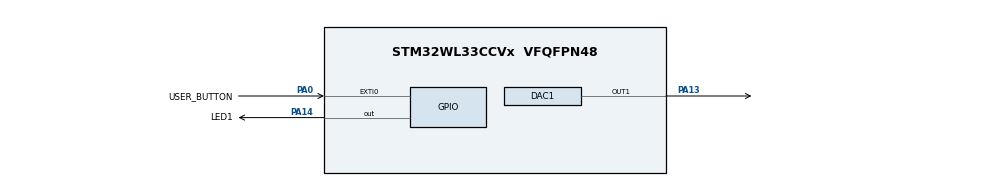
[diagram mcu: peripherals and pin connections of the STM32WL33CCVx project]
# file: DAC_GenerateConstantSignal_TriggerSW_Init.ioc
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DAC1.DAC_Trigger-DAC_OUT1=DAC_TRIGGER_SOFTWARE
Mcu.Family=STM32WL3
Mcu.Name=STM32WL33CCVx
Mcu.Package=VFQFPN48
NVIC.DAC_IRQn=true\:0\:0\:false\:false\:true\:true\:true\:true
NVIC.GPIOA_IRQn=true\:0\:0\:false\:false\:true\:true\:true\:true
OSCIN.Mode=HSE-External-Oscillator
OSCIN.Signal=RCC_OSC_IN
OSCOUT.Mode=HSE-External-Oscillator
OSCOUT.Signal=RCC_OSC_OUT
PA0.GPIO_Label=USER_BUTTON
PA0.GPIO_ModeDefaultEXTI=GPIO_MODE_IT_FALLING
PA0.GPIO_PuPd=GPIO_PULLUP
PA0.Signal=GPXTI0
PA13.Signal=COMP_DAC11_group
PA14.GPIO_Label=LED1
PA14.Signal=GPIO_Output
ProjectManager.HeapSize=0x000
ProjectManager.StackSize=0xC00
ProjectManager.TargetToolchain=EWARM V9.30
RCC.HSE_VALUE=48000000
RCC.HSI_VALUE=64000000
RCC.LSE_VALUE=32768
RCC.RC64MPLLSource=RCC_LSCOSOURCE_PLL64
SH.COMP_DAC11_group.0=DAC1_OUT1,DAC_OUT1
VP_PWR_VS_SECSignals.Mode=Security/Privilege
board=custom

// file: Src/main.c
/* USER CODE BEGIN Header */
/**
  ******************************************************************************
  * @file    Examples_LL/DAC/DAC_GenerateConstantSignal_TriggerSW_Init/Src/main.c
  * @author  MCD Application Team
  * @brief   This example describes how to use the DAC peripheral to generate
  *          a constant voltage signal.
  *          This example is based on the STM32WL3x DAC LL API;
  *          Peripheral initialization done using LL unitary services functions.
  ******************************************************************************
  * @attention
  *
  * Copyright (c) 2024 STMicroelectronics.
  * All rights reserved.
  *
  * This software is licensed under terms that can be found in the LICENSE file
  * in the root directory of this software component.
  * If no LICENSE file comes with this software, it is provided AS-IS.
  *
  ******************************************************************************
  */
/* USER CODE END Header */
#include "main.h"

/* USER CODE BEGIN PD */
/* Definitions of environment analog values */
  /* Value of analog reference voltage (Vref+), connected to analog voltage   */
  /* supply Vdda (unit: mV).                                                  */
  #define VDDA_APPLI                       ((uint32_t)3300)

/* Definitions of data related to this example */
  /* Full-scale digital value with a resolution of 6 bits (voltage range     */
  /* determined by analog voltage references Vref+ and Vref-,                 */
  /* refer to reference manual).                                              */
  #define DIGITAL_SCALE_6BITS             (__LL_DAC_DIGITAL_SCALE(LL_DAC_RESOLUTION_6B))

/* USER CODE END PD */

/* USER CODE BEGIN PV */
__IO uint8_t ubButtonPress = 0;
__IO uint8_t ubButtonPressCount = 0;

/* USER CODE END PV */

void SystemClock_Config(void);
void PeriphCommonClock_Config(void);
static void MX_GPIO_Init(void);
static void MX_DAC1_Init(void);
/* USER CODE BEGIN PFP */
void     Activate_DAC(void);
void     LED_On(void);
void     LED_Off(void);
void     LED_Toggle(void);
void     LED_Blinking(uint32_t Period);
void     WaitForUserButtonPress(void);
/* USER CODE END PFP */

int main(void)
{

  /* MCU Configuration--------------------------------------------------------*/

  /* Reset of all peripherals, Initializes the Flash interface and the Systick. */
  LL_APB0_GRP1_EnableClock(LL_APB0_GRP1_PERIPH_SYSCFG);

  /* USER CODE BEGIN Init */
  NVIC_SetPriorityGrouping(NVIC_PRIORITYGROUP_2);
  /* USER CODE END Init */

  /* Configure the system clock */
  SystemClock_Config();

  /* Configure the peripherals common clocks */
  PeriphCommonClock_Config();

  /* Initialize all configured peripherals */
  MX_GPIO_Init();
  MX_DAC1_Init();
  /* USER CODE BEGIN 2 */
  /* Wait for USER push-button press */
  WaitForUserButtonPress();

  /* Turn-off LD1 */
  LED_Off();

  /* Activate DAC channel */
  Activate_DAC();

  /* Turn-on LD1 */
  LED_On();
  /* USER CODE END 2 */

  /* Infinite loop */
  /* USER CODE BEGIN WHILE */
  while (1)
  {
    /* Note: LED state depending and DAC channel output are set into          */
    /*       function "UserButton_Callback()".                                */
    /* USER CODE END WHILE */

  }
}

void SystemClock_Config(void)
{

   /* Set HSE Capacitor Tuning */
  LL_RCC_HSE_SetCapacitorTuning(CFG_HW_RCC_HSE_CAPACITOR_TUNE);

   /* Set HSE startup Current */
 LL_RCC_HSE_SetStartupCurrent(0);

   /* Set HSE Amplitude Threshold */
 LL_RCC_HSE_SetAmplitudeThreshold(0);

   /* Set HSE Current Control */
  LL_RCC_HSE_SetCurrentControl(40);

   /* Enable the HSE */
  LL_RCC_HSE_Enable();

   /* Wait till HSE is ready */
  while(LL_RCC_HSE_IsReady() != 1)
  {
  }

  LL_FLASH_SetLatency(LL_FLASH_WAIT_STATES_1);

   /* Enable the RC64MPLL*/
  LL_RCC_RC64MPLL_Enable();

   /* Wait till RC64MPLL is ready */
  while(LL_RCC_RC64MPLL_IsReady() != 1)
  {
  }

  LL_RCC_SetRC64MPLLPrescaler(LL_RCC_RC64MPLL_DIV_1);

   /* Update the SystemCoreClock global variable */
  LL_SetSystemCoreClock(64000000);

   /* Configure the source of time base considering new system clocks settings*/
  LL_Init1msTick(64000000);
}

void PeriphCommonClock_Config(void)
{
  LL_RCC_SetSMPSPrescaler(LL_RCC_SMPS_DIV_2);

   /* Enable the KRM*/
  LL_RCC_KRM_Enable();
  LL_RCC_KRM_SetRateMultiplier(2);
}

static void MX_DAC1_Init(void)
{

  LL_DAC_InitTypeDef DAC_InitStruct = {0};

  LL_GPIO_InitTypeDef GPIO_InitStruct = {0};

  /* Peripheral clock enable */
  LL_APB0_GRP1_EnableClock(LL_APB0_GRP1_PERIPH_DAC);

  LL_AHB1_GRP1_EnableClock(LL_AHB1_GRP1_PERIPH_GPIOA);
  /**DAC1 GPIO Configuration
  PA13   ------> DAC1_OUT1
  */
  GPIO_InitStruct.Pin = LL_GPIO_PIN_13;
  GPIO_InitStruct.Mode = LL_GPIO_MODE_ANALOG;
  GPIO_InitStruct.Pull = LL_GPIO_PULL_NO;
  LL_GPIO_Init(GPIOA, &GPIO_InitStruct);

  /* DAC1 interrupt Init */
  NVIC_SetPriority(DAC_IRQn, 0);
  NVIC_EnableIRQ(DAC_IRQn);

  /** DAC channel OUT1 config
  */
  DAC_InitStruct.TriggerSource = LL_DAC_TRIG_SOFTWARE;
  DAC_InitStruct.WaveAutoGeneration = LL_DAC_WAVE_AUTO_GENERATION_NONE;
  DAC_InitStruct.OutputBuffer = LL_DAC_OUTPUT_BUFFER_ENABLE;
  LL_DAC_Init(DAC1, LL_DAC_CHANNEL_1, &DAC_InitStruct);
  LL_DAC_EnableTrigger(DAC1, LL_DAC_CHANNEL_1);

}

static void MX_GPIO_Init(void)
{
  LL_GPIO_InitTypeDef GPIO_InitStruct = {0};

  /* GPIO Ports Clock Enable */
  LL_AHB1_GRP1_EnableClock(LL_AHB1_GRP1_PERIPH_GPIOA);

  /**/
  LL_GPIO_ResetOutputPin(LED1_GPIO_Port, LED1_Pin);

  /**/
  LL_GPIO_SetPinPull(USER_BUTTON_GPIO_Port, USER_BUTTON_Pin, LL_GPIO_PULL_UP);

  /**/
  LL_EXTI_EnableIT(LL_EXTI_LINE_PA0);

  /**/
  LL_GPIO_SetPinMode(USER_BUTTON_GPIO_Port, USER_BUTTON_Pin, LL_GPIO_MODE_INPUT);

  /**/
  GPIO_InitStruct.Pin = LED1_Pin;
  GPIO_InitStruct.Mode = LL_GPIO_MODE_OUTPUT;
  GPIO_InitStruct.Speed = LL_GPIO_SPEED_FREQ_LOW;
  GPIO_InitStruct.OutputType = LL_GPIO_OUTPUT_PUSHPULL;
  GPIO_InitStruct.Pull = LL_GPIO_PULL_NO;
  LL_GPIO_Init(LED1_GPIO_Port, &GPIO_InitStruct);

  /* EXTI interrupt init*/
  NVIC_SetPriority(GPIOA_IRQn, 0);
  NVIC_EnableIRQ(GPIOA_IRQn);

}

/* USER CODE BEGIN 4 */

/**
  * @brief  Perform DAC activation procedure to make it ready to generate
  *         a voltage (DAC instance: DAC).
  * @note   Operations:
  *         - Enable DAC instance channel
  *         - Wait for DAC instance channel startup time
  * @param  None
  * @retval None
  */
void Activate_DAC(void)
{
  __IO uint32_t wait_loop_index = 0;

  /* Enable DAC channel */
  LL_DAC_Enable(DAC1, LL_DAC_CHANNEL_1);

  /* Delay for DAC channel voltage settling time from DAC channel startup.    */
  /* Compute number of CPU cycles to wait for, from delay in us.              */
  /* Note: Variable divided by 2 to compensate partially                      */
  /*       CPU processing cycles (depends on compilation optimization).       */
  /* Note: If system core clock frequency is below 200kHz, wait time          */
  /*       is only a few CPU processing cycles.                               */
  wait_loop_index = ((LL_DAC_DELAY_STARTUP_VOLTAGE_SETTLING_US * (SystemCoreClock / (100000 * 2))) / 10);
  while(wait_loop_index != 0)
  {
    wait_loop_index--;
  }

  /* Enable DAC channel trigger */
  /* Note: DAC channel conversion can start from trigger enable:              */
  /*       - if DAC channel trigger source is set to SW:                      */
  /*         DAC channel conversion will start after trig order               */
  /*         using function "LL_DAC_TrigSWConversion()".                      */
  /*       - if DAC channel trigger source is set to external trigger         */
  /*         (timer, ...):                                                    */
  /*         DAC channel conversion can start immediately                     */
  /*         (after next trig order from external trigger)                    */
  LL_DAC_EnableTrigger(DAC1, LL_DAC_CHANNEL_1);
}

/**
  * @brief  Turn-on LD1.
  * @param  None
  * @retval None
  */
void LED_On(void)
{
  /* Turn LD1 on */
  LL_GPIO_ResetOutputPin(LED1_GPIO_Port, LED1_Pin);
}

/**
  * @brief  Turn-off LD1.
  * @param  None
  * @retval None
  */
void LED_Off(void)
{
  /* Turn LD1 off */
  LL_GPIO_SetOutputPin(LED1_GPIO_Port, LED1_Pin);
}

/**
  * @brief  Toggle LD1.
  * @param  None
  * @retval None
  */
void LED_Toggle(void)
{
  /* Toggle LD1 */
  LL_GPIO_TogglePin(LED1_GPIO_Port, LED1_Pin);
}

/**
  * @brief  Set LD1 to Blinking mode for an infinite loop (toggle period based on value provided as input parameter).
  * @param  Period : Period of time (in ms) between each toggling of LED
  *   This parameter can be user defined values. Pre-defined values used in that example are :
  *     @arg LED_BLINK_FAST : Fast Blinking
  *     @arg LED_BLINK_SLOW : Slow Blinking
  *     @arg LED_BLINK_ERROR : Error specific Blinking
  * @retval None
  */
void LED_Blinking(uint32_t Period)
{
  /* Turn LD1 on */
  LL_GPIO_SetOutputPin(LED1_GPIO_Port, LED1_Pin);

  /* Toggle IO in an infinite loop */
  while (1)
  {
    LL_GPIO_TogglePin(LED1_GPIO_Port, LED1_Pin);
    LL_mDelay(Period);
  }
}

/**
  * @brief  Wait for USER push-button press to start transfer.
  * @param  None
  * @retval None
  */
void WaitForUserButtonPress(void)
{
  while (ubButtonPress == 0)
  {
    LL_GPIO_TogglePin(LED1_GPIO_Port, LED1_Pin);
    LL_mDelay(LED_BLINK_FAST);
  }
}

/******************************************************************************/
/*   USER IRQ HANDLER TREATMENT                                               */
/******************************************************************************/

/**
  * @brief  Function to manage IRQ Handler
  * @param  None
  * @retval None
  */
void UserButton_Callback(void)
{
  uint32_t tmp_dac_value = 0;

  /* On the first press on user button, update only user button variable      */
  /* to manage waiting function.                                              */
  /* Then, on next presses on user button, update DAC settings.               */
  if(ubButtonPress == 0)
  {
    /* Update USER push-button variable : to be checked in waiting loop in main program */
    ubButtonPress = 1;
  }
  else
  {
    ubButtonPressCount++;

    /* Set value for DAC output */
    if(ubButtonPressCount < 4)
    {
      /* Increase amplitude by a quarter each time button is pushed */
      tmp_dac_value = DIGITAL_SCALE_6BITS * ubButtonPressCount/4;

      /* Toggle LD1 */
      LED_Toggle();
    }
    else
    {
      /* Final amplitude: end of example */
      tmp_dac_value = DIGITAL_SCALE_6BITS;

      /* Turn-on LD1 */
      LED_On();
    }

    /* Set the data to be loaded in the data holding register */
    LL_DAC_ConvertData6RightAligned(DAC1, LL_DAC_CHANNEL_1, tmp_dac_value);

    /* Trig DAC conversion by software */
    LL_DAC_TrigSWConversion(DAC1, LL_DAC_CHANNEL_1);
  }
}

/**
  * @brief  DAC underrun interruption callback
  * @note   This function is executed when DAC channel underrun error occurs.
  * @retval None
  */
void DacUnderrunError_Callback(void)
{
  /* Note: Disable DAC interruption that caused this error before entering in */
  /*       infinite loop below.                                               */

  /* Disable interruption DAC channel1 underrun */
  LL_DAC_DisableIT_DMAUDR(DAC1);

  /* Error from ADC */
  LED_Blinking(LED_BLINK_ERROR);
}

/* USER CODE END 4 */

void Error_Handler(void)
{
}
